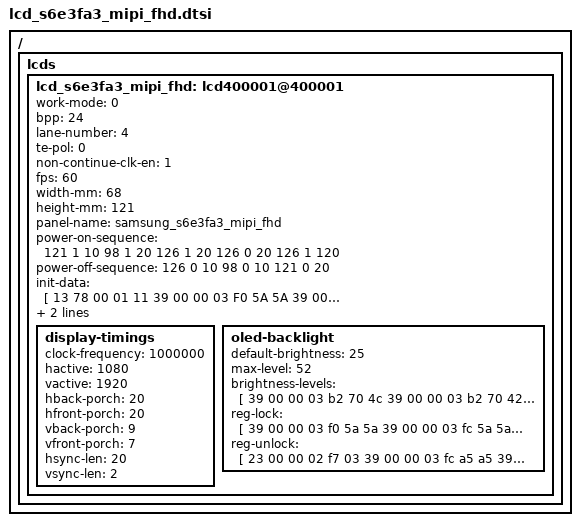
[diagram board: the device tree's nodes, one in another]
/ { lcds {
/*
* IC       :s6e3fa3
* module   :AMS549KU01
* source   :copy from AMS549KU01 datesheet
* Copyright:20160304  bring up whale2 board
------------------
* filename :lcd_s6e3fa3_mipi_fhd.dtsi
* FHD / OLED
* Read-id :  DA-0X40
*            DB-0X00
*            DC-0X01
*/
	lcd_s6e3fa3_mipi_fhd: lcd400001@400001 {

		work-mode = <0>;    /*command mode(0) or video mode(1)*/
		bpp = <24>;
		lane-number = <4>;

		te-pol = <0>;
		non-continue-clk-en = <1>;

		fps = <60>;
		width-mm = <68>;
		height-mm = <121>;
		panel-name = "samsung_s6e3fa3_mipi_fhd";

		power-on-sequence = <
					121  1  10
					98  1  20
					126  1  20
					126  0  20
					126  1  120
					>;
		power-off-sequence = <
					126  0  10
					98  0  10
					121  0  20
					>;

		init-data = [
			13 78 00 01 11
			39 00 00 03 F0 5A 5A
			39 00 00 03 FC 5A 5A
			23 00 00 02 35 00
			23 00 00 02 B0 1E
			23 00 00 02 FD B2
			23 00 00 02 CC 4C
			23 00 00 02 ED 44
			39 00 00 24 CA 01 00 01 00 01 00 80 80 80 80 80 80 80 80 80 80 80 80 80 80 80 80 80 80 80 80 80 80 80 80 00 00 00 00 00
			39 00 00 03 B2 40 E4
			39 00 00 03 B6 BC 04
			23 00 00 02 F7 03
			39 00 00 03 B6 BC 04
			23 00 00 02 B5 50
			23 00 00 02 53 00
			39 00 00 03 B6 BC 04
			23 00 00 02 B5 50
			23 00 00 02 55 02
			39 00 00 03 FC A5 A5
			39 78 00 03 F0 A5 A5
			13 78 00 01 29
			];

		sleep-in =  [
			13 0A 00 01 28
			13 78 00 01 10
			];
		sleep-out = [
			13 78 00 01 11
			13 64 00 01 29
			];

		display-timings {
			clock-frequency = <1000000>;
			hactive = <1080>;
			vactive = <1920>;
			hback-porch = <20>;
			hfront-porch = <20>;
			vback-porch = <9>;
			vfront-porch = <7>;
			hsync-len = <20>;
			vsync-len = <2>;
		};

		oled-backlight {
			default-brightness = <25>;
			max-level = <52>;
			brightness-levels = [
				39 00 00 03 b2 70 4c
				39 00 00 03 b2 70 42
				39 00 00 03 b2 70 33
				39 00 00 03 b2 70 1e
				39 00 00 03 b2 70 14
				39 00 00 03 b2 70 05
				39 00 00 03 b2 60 f6
				39 00 00 03 b2 60 e7
				39 00 00 03 b2 60 d6
				39 00 00 03 b2 60 c8
				39 00 00 03 b2 60 bA
				39 00 00 03 b2 60 ab
				39 00 00 03 b2 60 a1
				39 00 00 03 b2 60 82
				39 00 00 03 b2 60 6b
				39 00 00 03 b2 60 57
				39 00 00 03 b2 60 42
				39 00 00 03 b2 60 0d
				39 00 00 03 b2 50 f8
				39 00 00 03 b2 50 ce
				39 00 00 03 b2 50 98
				39 00 00 03 b2 50 7a
				39 00 00 03 b2 50 44
				39 00 00 03 b2 50 22
				39 00 00 03 b2 50 5A
				39 00 00 03 b2 40 e4
				39 00 00 03 b2 40 be
				39 00 00 03 b2 40 95
				39 00 00 03 b2 40 56
				39 00 00 03 b2 40 21
				39 00 00 03 b2 30 e3
				39 00 00 03 b2 30 a5
				39 00 00 03 b2 30 64
				39 00 00 03 b2 30 12
				39 00 00 03 b2 20 d5
				39 00 00 03 b2 20 c5
				39 00 00 03 b2 20 be
				39 00 00 03 b2 20 b5
				39 00 00 03 b2 20 a5
				39 00 00 03 b2 20 95
				39 00 00 03 b2 20 75
				39 00 00 03 b2 20 55
				39 00 00 03 b2 20 35
				39 00 00 03 b2 20 25
				39 00 00 03 b2 10 b6
				39 00 00 03 b2 10 59
				39 00 00 03 b2 00 f5
				39 00 00 03 b2 00 84
				39 00 00 03 b2 00 10
				39 00 00 03 b2 00 10
				39 00 00 03 b2 00 10
				39 00 00 03 b2 00 10
			];

			reg-lock = [
				39 00 00 03 f0 5a 5a
				39 00 00 03 fc 5a 5a
			];

			reg-unlock = [
				23 00 00 02 f7 03
				39 00 00 03 fc a5 a5
				39 00 00 03 f0 a5 a5
			];
		};
	};
};};

